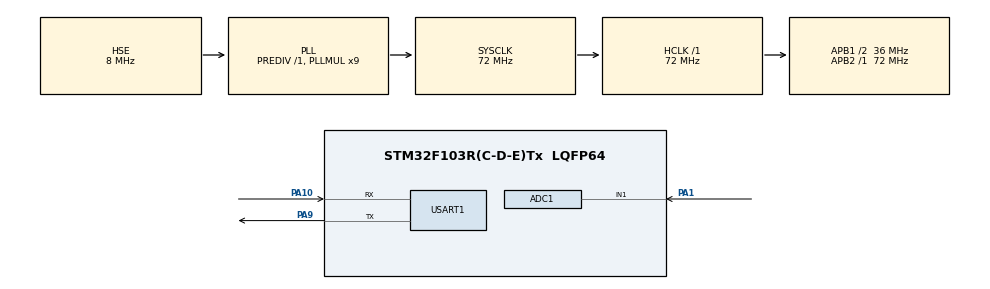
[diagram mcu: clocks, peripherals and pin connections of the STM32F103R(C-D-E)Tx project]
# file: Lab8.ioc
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ADC1.Channel-0\#ChannelRegularConversion=ADC_CHANNEL_1
ADC1.NbrOfConversionFlag=1
ADC1.Rank-0\#ChannelRegularConversion=1
ADC1.SamplingTime-0\#ChannelRegularConversion=ADC_SAMPLETIME_1CYCLE_5
ADC1.master=1
Mcu.Family=STM32F1
Mcu.Name=STM32F103R(C-D-E)Tx
Mcu.Package=LQFP64
NVIC.PriorityGroup=NVIC_PRIORITYGROUP_4
NVIC.USART1_IRQn=true\:0\:0\:false\:false\:true\:true\:true
PA1.Signal=ADCx_IN1
PA10.Mode=Asynchronous
PA10.Signal=USART1_RX
PA13.Signal=SYS_JTMS-SWDIO
PA14.Signal=SYS_JTCK-SWCLK
PA9.Mode=Asynchronous
PA9.Signal=USART1_TX
PD0-OSC_IN.Mode=HSE-External-Oscillator
PD0-OSC_IN.Signal=RCC_OSC_IN
PD1-OSC_OUT.Mode=HSE-External-Oscillator
PD1-OSC_OUT.Signal=RCC_OSC_OUT
ProjectManager.HeapSize=0x200
ProjectManager.StackSize=0x400
ProjectManager.TargetToolchain=STM32CubeIDE
RCC.ADCPresc=RCC_ADCPCLK2_DIV6
RCC.AHBFreq_Value=72000000
RCC.APB1CLKDivider=RCC_HCLK_DIV2
RCC.APB1Freq_Value=36000000
RCC.APB1TimFreq_Value=72000000
RCC.APB2Freq_Value=72000000
RCC.APB2TimFreq_Value=72000000
RCC.HCLKFreq_Value=72000000
RCC.PLLMUL=RCC_PLL_MUL9
RCC.PLLSourceVirtual=RCC_PLLSOURCE_HSE
RCC.SYSCLKFreq_VALUE=72000000
RCC.SYSCLKSource=RCC_SYSCLKSOURCE_PLLCLK
RCC.USBFreq_Value=72000000
SH.ADCx_IN1.0=ADC1_IN1,IN1
USART1.VirtualMode=VM_ASYNC
VP_SYS_VS_ND.Mode=No_Debug
board=custom

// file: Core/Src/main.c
/* USER CODE BEGIN Header */
/**
  ******************************************************************************
  * @file           : main.c
  * @brief          : Main program body
  ******************************************************************************
  * @attention
  *
  * <h2><center>&copy; Copyright (c) 2020 STMicroelectronics.
  * All rights reserved.</center></h2>
  *
  * This software component is licensed by ST under BSD 3-Clause license,
  * the "License"; You may not use this file except in compliance with the
  * License. You may obtain a copy of the License at:
  *                        opensource.org/licenses/BSD-3-Clause
  *
  ******************************************************************************
  */
/* USER CODE END Header */

#include "main.h"

/* USER CODE BEGIN Includes */
#include "lcd.h"
#include "stdio.h"
#include "string.h"
/* USER CODE END Includes */

/* USER CODE BEGIN PD */
#define N 200
#define M 1000
/* USER CODE END PD */

ADC_HandleTypeDef hadc1;

UART_HandleTypeDef huart1;

void SystemClock_Config(void);
static void MX_GPIO_Init(void);
static void MX_ADC1_Init(void);
static void MX_USART1_UART_Init(void);

int main(void)
{
  /* USER CODE BEGIN 1 */
	uint16_t raw = 0;
	float vol = 0;
	float tem = 0 ;
	char msg[N] = "";
	char buffer[M] = "";
	char *rec = buffer;
	char show[N][N] = {""};
	char test[N] = "temperature";
	int cnt = 0;
//	char bufferp[20];
  /* USER CODE END 1 */

  /* MCU Configuration--------------------------------------------------------*/

  /* Reset of all peripherals, Initializes the Flash interface and the Systick. */
  HAL_Init();

  /* Configure the system clock */
  SystemClock_Config();

  /* USER CODE BEGIN SysInit */
  LCD_Init();
  /* USER CODE END SysInit */

  /* Initialize all configured peripherals */
  MX_GPIO_Init();
  MX_ADC1_Init();
  MX_USART1_UART_Init();
  /* USER CODE BEGIN 2 */
  HAL_ADC_Start(&hadc1);
  /* USER CODE END 2 */

  /* Infinite loop */
  while (1)
  {

    /* USER CODE BEGIN 3 */
	  LCD_Clear(WHITE);

//	  ================================================================

	  HAL_ADC_Start(&hadc1);
	  // Wait for regular group conversion to be completed
	  HAL_ADC_PollForConversion(&hadc1, HAL_MAX_DELAY);
	  // Get ADC value
	  raw = HAL_ADC_GetValue(&hadc1); // the voltage should be raw * (3.3/4096)(12bits)
	  vol = raw * (3.3/4096);
	  tem = ((1.43 - vol) / 4.3) + 25;
	  //T = {(1.43 - V) / 4.3} + 25
	  sprintf(msg, "%f\r\n", tem); // @suppress("Float formatting support")

//	  =================================================================
	  HAL_UART_Receive_IT(&huart1, buffer, M);
//	  strcpy(buffer, test);
	  if (strlen(rec) > 0){
		  for(int i = 0; i < strlen(rec); ++i){
			  show[cnt][i] = rec[i];
		  }
		  ++cnt;
//		  sprintf(msg, "%d\r\n", cnt);
//		  HAL_UART_Transmit(&huart1, msg, sizeof(msg), 200);

//		  HAL_UART_Transmit(&huart1, rec, sizeof(char) * strlen(rec), 200);
	  }
	  rec = buffer + strlen(buffer);
//	  =================================================================

	  POINT_COLOR = RED;
//	  LCD_ShowString(30, 40, 200, 24, 24, (uint8_t*) "Mini STM32 ^_^");
	  if(!strcmp(show[cnt-1], test)){
		  HAL_UART_Transmit(&huart1, rec, sizeof(char) * strlen(rec), 200);
		  LCD_ShowString(30, 300, 500, 16, 16, (uint8_t*) msg);
	  }
	  POINT_COLOR = GREEN;
	  LCD_DrawRectangle(30, 30, 230, 260);
	  POINT_COLOR = BLACK;
//	  LCD_Fill(31, 151, 209, 189, YELLOW);
//	  LCD_ShowString(30, 90, 200, 16, 16, (uint8_t*) buffer);

	  int sizeFont = 24;    //这里可以自己设置默认字体大小

	  int maxColumn = lcddev.width/(sizeFont/2);
	  int maxRow = lcddev.height/sizeFont - 2;

	  int x = 2, pnt = cnt - 1, len, rs, a, b, y;
	  while(x < maxRow && pnt >= 0){
		  len = strlen(show[pnt]);
		  rs = ((len - 1) / (maxColumn-6)) + 1;
		  if(rs > 1) y = 6;
		  else y = maxColumn - len;
		  for(int i = 0; i < len; ++i, ++y){
			  if (y >= maxColumn){
				  y = 6;
				  x ++;
				  if(x >= maxRow)
					  break;
			  }
			  a=y*sizeFont/2;    //这里面好像是字体24，实际上仅仅�?12的宽度罢了，�?24的字体是12*24的，并不是正方形
			  b=x*sizeFont;
			  LCD_ShowChar(a, b, show[pnt][i],sizeFont,0);
		  }
		  ++x;
		  --pnt;
	  }

//	  LCDshowString_my(0,0,show);
	  HAL_Delay(2000);

  }
  /* USER CODE END 3 */
}

void SystemClock_Config(void)
{
  RCC_OscInitTypeDef RCC_OscInitStruct = {0};
  RCC_ClkInitTypeDef RCC_ClkInitStruct = {0};
  RCC_PeriphCLKInitTypeDef PeriphClkInit = {0};

  /** Initializes the CPU, AHB and APB busses clocks
  */
  RCC_OscInitStruct.OscillatorType = RCC_OSCILLATORTYPE_HSE;
  RCC_OscInitStruct.HSEState = RCC_HSE_ON;
  RCC_OscInitStruct.HSEPredivValue = RCC_HSE_PREDIV_DIV1;
  RCC_OscInitStruct.HSIState = RCC_HSI_ON;
  RCC_OscInitStruct.PLL.PLLState = RCC_PLL_ON;
  RCC_OscInitStruct.PLL.PLLSource = RCC_PLLSOURCE_HSE;
  RCC_OscInitStruct.PLL.PLLMUL = RCC_PLL_MUL9;
  if (HAL_RCC_OscConfig(&RCC_OscInitStruct) != HAL_OK)
  {
    Error_Handler();
  }
  /** Initializes the CPU, AHB and APB busses clocks
  */
  RCC_ClkInitStruct.ClockType = RCC_CLOCKTYPE_HCLK|RCC_CLOCKTYPE_SYSCLK
                              |RCC_CLOCKTYPE_PCLK1|RCC_CLOCKTYPE_PCLK2;
  RCC_ClkInitStruct.SYSCLKSource = RCC_SYSCLKSOURCE_PLLCLK;
  RCC_ClkInitStruct.AHBCLKDivider = RCC_SYSCLK_DIV1;
  RCC_ClkInitStruct.APB1CLKDivider = RCC_HCLK_DIV2;
  RCC_ClkInitStruct.APB2CLKDivider = RCC_HCLK_DIV1;

  if (HAL_RCC_ClockConfig(&RCC_ClkInitStruct, FLASH_LATENCY_2) != HAL_OK)
  {
    Error_Handler();
  }
  PeriphClkInit.PeriphClockSelection = RCC_PERIPHCLK_ADC;
  PeriphClkInit.AdcClockSelection = RCC_ADCPCLK2_DIV6;
  if (HAL_RCCEx_PeriphCLKConfig(&PeriphClkInit) != HAL_OK)
  {
    Error_Handler();
  }
}

static void MX_ADC1_Init(void)
{

  ADC_ChannelConfTypeDef sConfig = {0};

  /** Common config
  */
  hadc1.Instance = ADC1;
  hadc1.Init.ScanConvMode = ADC_SCAN_DISABLE;
  hadc1.Init.ContinuousConvMode = DISABLE;
  hadc1.Init.DiscontinuousConvMode = DISABLE;
  hadc1.Init.ExternalTrigConv = ADC_SOFTWARE_START;
  hadc1.Init.DataAlign = ADC_DATAALIGN_RIGHT;
  hadc1.Init.NbrOfConversion = 1;
  if (HAL_ADC_Init(&hadc1) != HAL_OK)
  {
    Error_Handler();
  }
  /** Configure Regular Channel
  */
  sConfig.Channel = ADC_CHANNEL_1;
  sConfig.Rank = ADC_REGULAR_RANK_1;
  sConfig.SamplingTime = ADC_SAMPLETIME_1CYCLE_5;
  if (HAL_ADC_ConfigChannel(&hadc1, &sConfig) != HAL_OK)
  {
    Error_Handler();
  }

}

static void MX_USART1_UART_Init(void)
{

  huart1.Instance = USART1;
  huart1.Init.BaudRate = 115200;
  huart1.Init.WordLength = UART_WORDLENGTH_8B;
  huart1.Init.StopBits = UART_STOPBITS_1;
  huart1.Init.Parity = UART_PARITY_NONE;
  huart1.Init.Mode = UART_MODE_TX_RX;
  huart1.Init.HwFlowCtl = UART_HWCONTROL_NONE;
  huart1.Init.OverSampling = UART_OVERSAMPLING_16;
  if (HAL_UART_Init(&huart1) != HAL_OK)
  {
    Error_Handler();
  }

}

static void MX_GPIO_Init(void)
{

  /* GPIO Ports Clock Enable */
  __HAL_RCC_GPIOD_CLK_ENABLE();
  __HAL_RCC_GPIOA_CLK_ENABLE();

}

/* USER CODE BEGIN 4 */
void LCDshowString_my(int columnIndex,int rowIndex,unsigned char* str)
{
    int i=0;
    int a,b,c;

    int maxColumn;
    int maxRow;

    int sizeFont = 24;    //这里可以自己设置默认字体大小

    maxColumn = lcddev.width/(sizeFont/2);
    maxRow = lcddev.height/sizeFont;

    while( (*str)!='\0' )
    {
        a=i+columnIndex;    //第几个字符了
        b=a%maxColumn*sizeFont/2;    //这里面好像是字体24，实际上仅仅�?12的宽度罢了，�?24的字体是12*24的，并不是正方形
        c=rowIndex*sizeFont + a/maxColumn*sizeFont;
        LCD_ShowChar(b, c,*str,sizeFont,0);
        str++;
        i++;
    }
}

/* USER CODE END 4 */

void Error_Handler(void)
{
}

/************************ (C) COPYRIGHT STMicroelectronics *****END OF FILE****/
